# cbass_CBASS_ISC_45818000h register map
Vendor: Texas Instruments
Peripheral module from a debugger description file (folder am62D).
Registers are 32-bit, read-write, reset 0x0 unless marked. A register's access mark holds for its fields unless they carry their own. Offsets are as the file gives them; lines under a group give offsets from that group; [hi:lo] are bit positions; {n}, {i} and the like mark numbered series; 'fields as' and 'values as' point back to an identical list; <NAME> marks a mode.

## cbass_isc
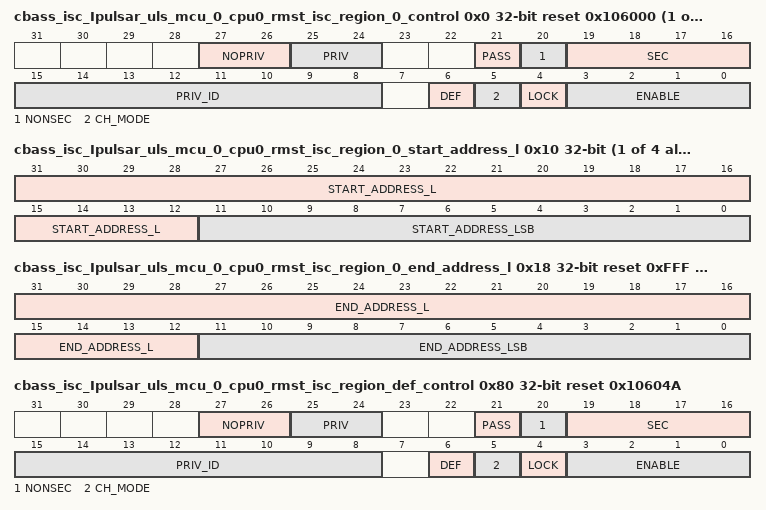
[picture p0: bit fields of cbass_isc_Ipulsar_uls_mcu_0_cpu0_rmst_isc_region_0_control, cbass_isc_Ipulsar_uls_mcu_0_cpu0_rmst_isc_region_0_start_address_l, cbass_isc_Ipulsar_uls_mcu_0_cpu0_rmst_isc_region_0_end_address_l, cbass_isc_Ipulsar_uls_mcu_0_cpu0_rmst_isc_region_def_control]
{0x0+0x20*i} cbass_isc_Ipulsar_uls_mcu_0_cpu0_rmst_isc_region_{i}_control access not given reset 0x106000 (i=0..3) — The ISC Region {i} Control Register defines the control fields for the master Ipulsar_uls_mcu_0.cpu0_rmst region {i} ISC.
  [27:26] NOPRIV rw — Clear output priv attribute. If each bit is set then the outgoing priv bit is cleared. Reset Source: domain_default_rst_mod_g_rst_n
  [25:24] PRIV rw — Set outgoing priv attribute. If each bit is set then the outgoing priv bit is set. Reset Source: domain_default_rst_mod_g_rst_n
  [21] PASS rw — No privID replacement, pass through value. Reset Source: domain_default_rst_mod_g_rst_n
  [20] NONSEC rw — Make outgoing non-secure. Reset Source: domain_default_rst_mod_g_rst_n
  [19:16] SEC rw — Make outgoing secure. A value of 0xA enables, others disable. Reset Source: domain_default_rst_mod_g_rst_n
  [15:8] PRIV_ID rw — Priv ID. Reset Source: domain_default_rst_mod_g_rst_n
  [6] DEF ro — Default region indication. The default region is used when all other regions do not match. Reset Source: domain_default_rst_mod_g_rst_n
  [5] CH_MODE rw — Enable channel mode to match region to a chanid value. Otherwise use address mode to match region to an address range. Reset Source: domain_default_rst_mod_g_rst_n
  [4] LOCK — Lock region. Once set the region values cannot be modified. Reset Source: domain_default_rst_mod_g_rst_n (access R/W1TS)
  [3:0] ENABLE rw — Enable region. A value of 0xA enables, others disable. Reset Source: domain_default_rst_mod_g_rst_n
{0x10+0x20*i} cbass_isc_Ipulsar_uls_mcu_0_cpu0_rmst_isc_region_{i}_start_address_l (i=0..3) — The ISC Region {i} Start Address Low Register defines the start address bits 31 to 0 for the master Ipulsar_uls_mcu_0.cpu0_rmst region {i} ISC.
  [31:12] START_ADDRESS_L — Start address bits 31 to 12. Reset Source: domain_default_rst_mod_g_rst_n
  [11:0] START_ADDRESS_LSB — Start address bits 11 to 0 must be 0 as address must be 4KB aligned in address mode. Can also be channel number in channel mode. Reset Source: domain_default_rst_mod_g_rst_n
{0x14+0x20*i} cbass_isc_Ipulsar_uls_mcu_0_cpu0_rmst_isc_region_{i}_start_address_h (i=0..3) — The ISC Region {i} Start Address High Register defines the start address bits 47 to 32 for the master Ipulsar_uls_mcu_0.cpu0_rmst region {i} ISC.
  [15:0] START_ADDRESS_H — Start address bits 47 to 32. Reset Source: domain_default_rst_mod_g_rst_n
{0x18+0x20*i} cbass_isc_Ipulsar_uls_mcu_0_cpu0_rmst_isc_region_{i}_end_address_l access per field reset 0xFFF (i=0..3) — The ISC Region {i} End Address Low Register defines the end included address bits 31 to 0 for the master Ipulsar_uls_mcu_0.cpu0_rmst region {i} ISC.
  [31:12] END_ADDRESS_L rw — End address bits 31 to 12 to include in the match. Reset Source: domain_default_rst_mod_g_rst_n
  [11:0] END_ADDRESS_LSB ro — End address bits 11 to 0 are forced to Fs as address must be 4KB aligned. Reset Source: domain_default_rst_mod_g_rst_n
{0x1C+0x20*i} cbass_isc_Ipulsar_uls_mcu_0_cpu0_rmst_isc_region_{i}_end_address_h (i=0..3) — The ISC Region {i} End Address High Register defines the end address bits 47 to 32 for the master Ipulsar_uls_mcu_0.cpu0_rmst region {i} ISC.
  [15:0] END_ADDRESS_H — End address bits 47 to 32. Reset Source: domain_default_rst_mod_g_rst_n
0x80 cbass_isc_Ipulsar_uls_mcu_0_cpu0_rmst_isc_region_def_control access not given reset 0x10604A — The ISC Default Region Control Register defines the control fields for the master Ipulsar_uls_mcu_0.cpu0_rmst region 4 ISC.
  [27:26] NOPRIV rw — Clear output priv attribute. If each bit is set then the outgoing priv bit is cleared, else the bit is unchanged. Do not set both priv and nopriv for the same bit. Reset Source: domain_default_rst_mod_g_rst_n
  [25:24] PRIV rw — Set outgoing priv attribute. If each bit is set then the outgoing priv bit is set, else the bit is unchanged. Do not set both priv and nopriv for the same bit. Reset Source: domain_default_rst_mod_g_rst_n
  [21] PASS rw — No privID replacement. A value of 1 will pass through privid value. A value of 0 will replace privid with priv_id field value. Reset Source: domain_default_rst_mod_g_rst_n
  [20] NONSEC rw — Make outgoing non-secure. A value of 1 forces secure clear, others do nothing. Do not set both sec and nonsec. Reset Source: domain_default_rst_mod_g_rst_n
  [19:16] SEC rw — Make outgoing secure. A value of 0xA forces secure set, others do nothing. Do not set both sec and nonsec. Reset Source: domain_default_rst_mod_g_rst_n
  [15:8] PRIV_ID rw — Priv ID value to use if pass is 0. Reset Source: domain_default_rst_mod_g_rst_n
  [6] DEF ro — Default region indication. The default region is used when all other regions do not match. Reset Source: domain_default_rst_mod_g_rst_n
  [5] CH_MODE ro — Enable channel mode to match region to a chanid value. Otherwise use address mode to match region to an address range. Reset Source: domain_default_rst_mod_g_rst_n
  [4] LOCK — Lock region. Once set, the region values cannot be modified. Reset Source: domain_default_rst_mod_g_rst_n (access R/W1TS)
  [3:0] ENABLE ro — Enable region. A value of 0xA enables, others disable. Reset Source: domain_default_rst_mod_g_rst_n
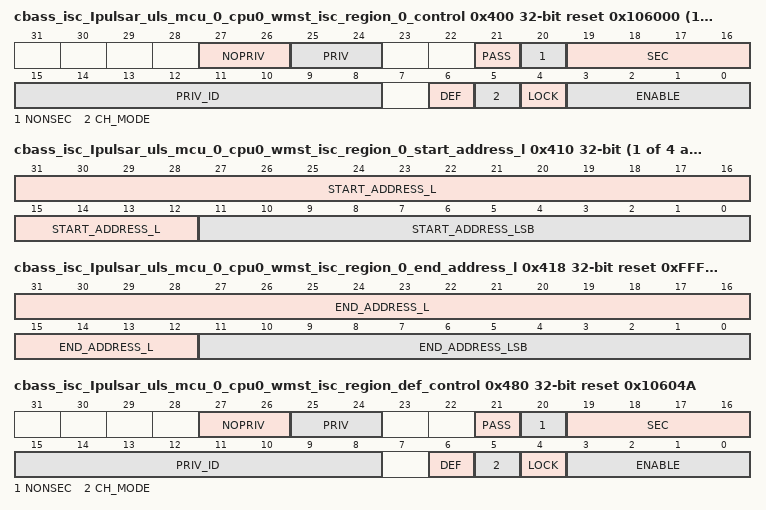
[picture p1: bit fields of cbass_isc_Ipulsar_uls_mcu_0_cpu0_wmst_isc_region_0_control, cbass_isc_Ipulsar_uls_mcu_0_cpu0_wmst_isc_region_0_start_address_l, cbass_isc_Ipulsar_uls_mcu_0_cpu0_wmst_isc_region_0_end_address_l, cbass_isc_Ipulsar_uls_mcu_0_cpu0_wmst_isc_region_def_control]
{0x400+0x20*i} cbass_isc_Ipulsar_uls_mcu_0_cpu0_wmst_isc_region_{i}_control access not given reset 0x106000 (i=0..3) — The ISC Region {i} Control Register defines the control fields for the master Ipulsar_uls_mcu_0.cpu0_wmst region {i} ISC.
  fields as cbass_isc_Ipulsar_uls_mcu_0_cpu0_rmst_isc_region_0_control
{0x410+0x20*i} cbass_isc_Ipulsar_uls_mcu_0_cpu0_wmst_isc_region_{i}_start_address_l (i=0..3) — The ISC Region {i} Start Address Low Register defines the start address bits 31 to 0 for the master Ipulsar_uls_mcu_0.cpu0_wmst region {i} ISC.
  fields as cbass_isc_Ipulsar_uls_mcu_0_cpu0_rmst_isc_region_0_start_address_l
{0x414+0x20*i} cbass_isc_Ipulsar_uls_mcu_0_cpu0_wmst_isc_region_{i}_start_address_h (i=0..3) — The ISC Region {i} Start Address High Register defines the start address bits 47 to 32 for the master Ipulsar_uls_mcu_0.cpu0_wmst region {i} ISC.
  fields as cbass_isc_Ipulsar_uls_mcu_0_cpu0_rmst_isc_region_0_start_address_h
{0x418+0x20*i} cbass_isc_Ipulsar_uls_mcu_0_cpu0_wmst_isc_region_{i}_end_address_l access per field reset 0xFFF (i=0..3) — The ISC Region {i} End Address Low Register defines the end included address bits 31 to 0 for the master Ipulsar_uls_mcu_0.cpu0_wmst region {i} ISC.
  fields as cbass_isc_Ipulsar_uls_mcu_0_cpu0_rmst_isc_region_0_end_address_l
{0x41C+0x20*i} cbass_isc_Ipulsar_uls_mcu_0_cpu0_wmst_isc_region_{i}_end_address_h (i=0..3) — The ISC Region {i} End Address High Register defines the end address bits 47 to 32 for the master Ipulsar_uls_mcu_0.cpu0_wmst region {i} ISC.
  fields as cbass_isc_Ipulsar_uls_mcu_0_cpu0_rmst_isc_region_0_end_address_h
0x480 cbass_isc_Ipulsar_uls_mcu_0_cpu0_wmst_isc_region_def_control access not given reset 0x10604A — The ISC Default Region Control Register defines the control fields for the master Ipulsar_uls_mcu_0.cpu0_wmst region 4 ISC.
  fields as cbass_isc_Ipulsar_uls_mcu_0_cpu0_rmst_isc_region_def_control
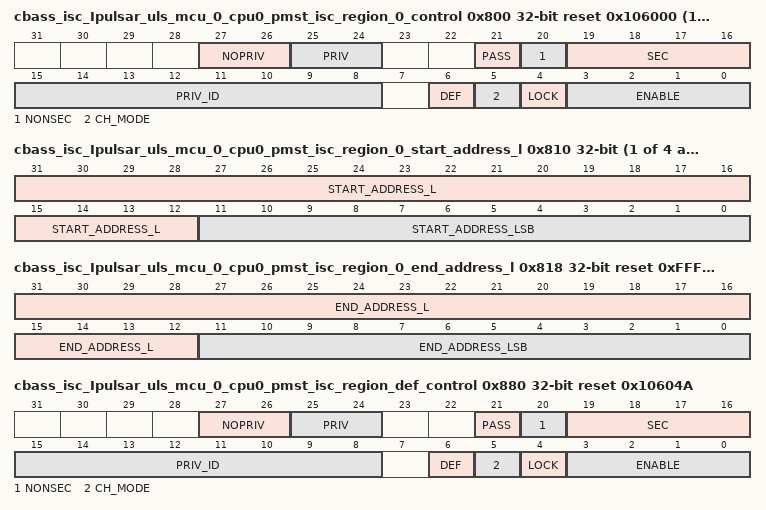
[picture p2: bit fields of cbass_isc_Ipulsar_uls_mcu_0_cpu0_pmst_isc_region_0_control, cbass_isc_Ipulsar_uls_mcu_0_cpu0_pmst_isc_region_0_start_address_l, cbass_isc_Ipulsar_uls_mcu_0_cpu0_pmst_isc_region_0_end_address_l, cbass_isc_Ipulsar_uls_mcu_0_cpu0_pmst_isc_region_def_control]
{0x800+0x20*i} cbass_isc_Ipulsar_uls_mcu_0_cpu0_pmst_isc_region_{i}_control access not given reset 0x106000 (i=0..3) — The ISC Region {i} Control Register defines the control fields for the master Ipulsar_uls_mcu_0.cpu0_pmst region {i} ISC.
  fields as cbass_isc_Ipulsar_uls_mcu_0_cpu0_rmst_isc_region_0_control
{0x810+0x20*i} cbass_isc_Ipulsar_uls_mcu_0_cpu0_pmst_isc_region_{i}_start_address_l (i=0..3) — The ISC Region {i} Start Address Low Register defines the start address bits 31 to 0 for the master Ipulsar_uls_mcu_0.cpu0_pmst region {i} ISC.
  fields as cbass_isc_Ipulsar_uls_mcu_0_cpu0_rmst_isc_region_0_start_address_l
{0x814+0x20*i} cbass_isc_Ipulsar_uls_mcu_0_cpu0_pmst_isc_region_{i}_start_address_h (i=0..3) — The ISC Region {i} Start Address High Register defines the start address bits 47 to 32 for the master Ipulsar_uls_mcu_0.cpu0_pmst region {i} ISC.
  fields as cbass_isc_Ipulsar_uls_mcu_0_cpu0_rmst_isc_region_0_start_address_h
{0x818+0x20*i} cbass_isc_Ipulsar_uls_mcu_0_cpu0_pmst_isc_region_{i}_end_address_l access per field reset 0xFFF (i=0..3) — The ISC Region {i} End Address Low Register defines the end included address bits 31 to 0 for the master Ipulsar_uls_mcu_0.cpu0_pmst region {i} ISC.
  fields as cbass_isc_Ipulsar_uls_mcu_0_cpu0_rmst_isc_region_0_end_address_l
{0x81C+0x20*i} cbass_isc_Ipulsar_uls_mcu_0_cpu0_pmst_isc_region_{i}_end_address_h (i=0..3) — The ISC Region {i} End Address High Register defines the end address bits 47 to 32 for the master Ipulsar_uls_mcu_0.cpu0_pmst region {i} ISC.
  fields as cbass_isc_Ipulsar_uls_mcu_0_cpu0_rmst_isc_region_0_end_address_h
0x880 cbass_isc_Ipulsar_uls_mcu_0_cpu0_pmst_isc_region_def_control access not given reset 0x10604A — The ISC Default Region Control Register defines the control fields for the master Ipulsar_uls_mcu_0.cpu0_pmst region 4 ISC.
  fields as cbass_isc_Ipulsar_uls_mcu_0_cpu0_rmst_isc_region_def_control
